# ESP32-H4 register map
Vendor: ESPRESSIF SYSTEMS (SHANGHAI) CO., LTD.; Series: ESP32 H-Series; File version: 1
CPU: RV32IMAC r0p0, little endian, no MPU, no FPU, 0 interrupt priority bits
Address unit: 32 bits
Registers are 32-bit, read-write, reset 0x0 unless marked. A register's access mark holds for its fields unless they carry their own. Offsets are from the block's base; [hi:lo] are bit positions; {n}, {i} and the like mark numbered series.

## UHCI0 — Universal Host Controller Interface 0
Base 0x60014000
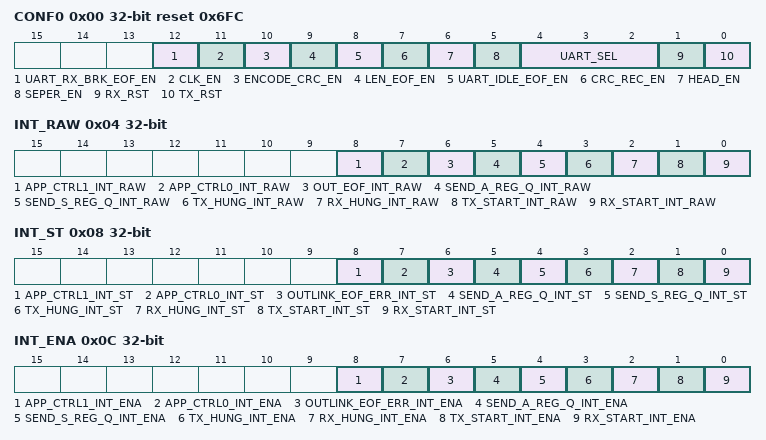
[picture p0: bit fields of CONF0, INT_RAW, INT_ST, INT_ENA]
0x00 CONF0 reset 0x6FC — UHCI configuration register
  [12] UART_RX_BRK_EOF_EN — Configures whether or not to stop UHCI from receiving data after UART has received a NULL frame.\\ 0: Not stop\\ 1: Stop\\
  [11] CLK_EN — Configures clock gating.\\ 0: Support clock only when the application writes registers.\\ 1: Always force the clock on for registers.\\
  [10] ENCODE_CRC_EN — Configures whether or not to enable data integrity check by appending a 16 bit CCITT-CRC to the end of the data.\\ 0: Disable\\ 1: Enable\\
  [9] LEN_EOF_EN — Configures when the UHCI decoder stops receiving data.\\ 0: Stops after receiving 0xC0\\ 1: Stops when the number of received data bytes reach the specified value. When UHCI_HEAD_EN is 1, the specified value is the data length indicated by the UHCI packet header. when UHCI_HEAD_EN is 0, the specified value is the configured value.\\
  [8] UART_IDLE_EOF_EN — Configures whether or not to stop receiving data when UART is idle.\\ 0: Not stop\\ 1: Stop\\
  [7] CRC_REC_EN — Configures whether or not to enable the reception of the 16-bit CRC.\\ 0: Disable\\ 1: Enable\\
  [6] HEAD_EN — Configures whether or not to encode the data packet with a formatting header.\\ 0: Not use formatting header\\ 1: Use formatting header\\
  [5] SEPER_EN — Configures whether or not to separate the data frame with a special character.\\ 0: Not separate\\ 1: Separate\\
  [4:2] UART_SEL — Configures to select which uart to connect with UHCI.\\ 0: UART0\\ 1: UART1\\
  [1] RX_RST — Write 1 and then write 0 to reset the encoder state machine.
  [0] TX_RST — Write 1 and then write 0 to reset the decoder state machine.
0x04 INT_RAW — Raw interrupt status
  [8] APP_CTRL1_INT_RAW — The raw interrupt status of UHCI_APP_CTRL1_INT.
  [7] APP_CTRL0_INT_RAW — The raw interrupt status of UHCI_APP_CTRL0_INT.
  [6] OUT_EOF_INT_RAW — The raw interrupt status of UHCI_OUT_EOF_INT.
  [5] SEND_A_REG_Q_INT_RAW — The raw interrupt status of UHCI_SEND_A_REG_Q_INT.
  [4] SEND_S_REG_Q_INT_RAW — The raw interrupt status of UHCI_SEND_S_REG_Q_INT.
  [3] TX_HUNG_INT_RAW — The raw interrupt status of UHCI_TX_HUNG_INT.
  [2] RX_HUNG_INT_RAW — The raw interrupt status of UHCI_RX_HUNG_INT.
  [1] TX_START_INT_RAW — The raw interrupt status of UHCI_TX_START_INT.
  [0] RX_START_INT_RAW — The raw interrupt status of UHCI_RX_START_INT.
0x08 INT_ST ro — Masked interrupt status
  [8] APP_CTRL1_INT_ST — The masked interrupt status of UHCI_APP_CTRL1_INT.
  [7] APP_CTRL0_INT_ST — The masked interrupt status of UHCI_APP_CTRL0_INT.
  [6] OUTLINK_EOF_ERR_INT_ST — The masked interrupt status of UHCI_OUTLINK_EOF_ERR_INT.
  [5] SEND_A_REG_Q_INT_ST — The masked interrupt status of UHCI_SEND_A_REG_Q_INT.
  [4] SEND_S_REG_Q_INT_ST — The masked interrupt status of UHCI_SEND_S_REG_Q_INT.
  [3] TX_HUNG_INT_ST — The masked interrupt status of UHCI_TX_HUNG_INT.
  [2] RX_HUNG_INT_ST — The masked interrupt status of UHCI_RX_HUNG_INT.
  [1] TX_START_INT_ST — The masked interrupt status of UHCI_TX_START_INT.
  [0] RX_START_INT_ST — The masked interrupt status of UHCI_RX_START_INT.
0x0C INT_ENA — Interrupt enable bits
  [8] APP_CTRL1_INT_ENA — Write 1 to enable UHCI_APP_CTRL1_INT.
  [7] APP_CTRL0_INT_ENA — Write 1 to enable UHCI_APP_CTRL0_INT.
  [6] OUTLINK_EOF_ERR_INT_ENA — Write 1 to enable UHCI_OUTLINK_EOF_ERR_INT.
  [5] SEND_A_REG_Q_INT_ENA — Write 1 to enable UHCI_SEND_A_REG_Q_INT.
  [4] SEND_S_REG_Q_INT_ENA — Write 1 to enable UHCI_SEND_S_REG_Q_INT.
  [3] TX_HUNG_INT_ENA — Write 1 to enable UHCI_TX_HUNG_INT.
  [2] RX_HUNG_INT_ENA — Write 1 to enable UHCI_RX_HUNG_INT.
  [1] TX_START_INT_ENA — Write 1 to enable UHCI_TX_START_INT.
  [0] RX_START_INT_ENA — Write 1 to enable UHCI_RX_START_INT.
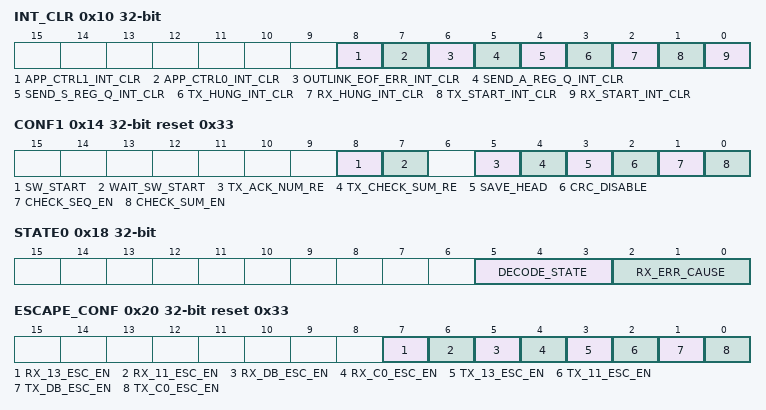
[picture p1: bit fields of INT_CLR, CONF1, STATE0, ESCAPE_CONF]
0x10 INT_CLR wo — Interrupt clear bits
  [8] APP_CTRL1_INT_CLR — Write 1 to clear UHCI_APP_CTRL1_INT.
  [7] APP_CTRL0_INT_CLR — Write 1 to clear UHCI_APP_CTRL0_INT.
  [6] OUTLINK_EOF_ERR_INT_CLR — Write 1 to clear UHCI_OUTLINK_EOF_ERR_INT.
  [5] SEND_A_REG_Q_INT_CLR — Write 1 to clear UHCI_SEND_A_REG_Q_INT.
  [4] SEND_S_REG_Q_INT_CLR — Write 1 to clear UHCI_SEND_S_REG_Q_INT.
  [3] TX_HUNG_INT_CLR — Write 1 to clear UHCI_TX_HUNG_INT.
  [2] RX_HUNG_INT_CLR — Write 1 to clear UHCI_RX_HUNG_INT.
  [1] TX_START_INT_CLR — Write 1 to clear UHCI_TX_START_INT.
  [0] RX_START_INT_CLR — Write 1 to clear UHCI_RX_START_INT.
0x14 CONF1 access per field reset 0x33 — UHCI configuration register
  [8] SW_START wo — Write 1 to send data packets when the encoder state machine is in ST_SW_WAIT state.
  [7] WAIT_SW_START rw — Configures whether or not to put the UHCI encoder state machine to ST_SW_WAIT state.\\ 0: No\\ 1: Yes\\
  [5] TX_ACK_NUM_RE rw — Configures whether or not to encode the data packet with an acknowledgment when a reliable packet is to be transmitted.\\ 0: Not use acknowledgement\\ 1: Use acknowledgement\\
  [4] TX_CHECK_SUM_RE rw — Configures whether or not to encode the data packet with a checksum.\\ 0: Not use checksum\\ 1: Use checksum\\
  [3] SAVE_HEAD rw — Configures whether or not to save the packet header when UHCI receives a data packet.\\ 0: Not save\\ 1: Save\\
  [2] CRC_DISABLE rw — Configures whether or not to enable CRC calculation.\\ 0: Disable\\ 1: Enable\\ Valid only when the Data Integrity Check Present bit in UHCI packet is 1.\\
  [1] CHECK_SEQ_EN rw — Configures whether or not to enable the sequence number check when UHCI receives a data packet.\\ 0: Disable\\ 1: Enable\\
  [0] CHECK_SUM_EN rw — Configures whether or not to enable header checksum validation when UHCI receives a data packet.\\ 0: Disable\\ 1: Enable\\
0x18 STATE0 ro — UHCI receive status
  [5:3] DECODE_STATE — Represents the UHCI decoder status.
  [2:0] RX_ERR_CAUSE — Represents the error type when DMA has received a packet with error.\\ 0: Invalid. No effect\\ 1: Checksum error in the HCI packet\\ 2: Sequence number error in the HCI packet\\ 3: CRC bit error in the HCI packet\\ 4: 0xC0 is found but the received HCI packet is not complete\ 5: 0xC0 is not found when the HCI packet has been received\\ 6: CRC check error\\ 7: Invalid. No effect\\
0x1C STATE1 ro — UHCI transmit status
  [2:0] ENCODE_STATE — Represents the UHCI encoder status.
0x20 ESCAPE_CONF reset 0x33 — Escape character configuration
  [7] RX_13_ESC_EN — Configures whether or not to replace flow control character 0x13 by special characters when DMA sends data.\\ 0: Not replace\\ 1: Replace\\
  [6] RX_11_ESC_EN — Configures whether or not to replace flow control character 0x11 by special characters when DMA sends data.\\ 0: Not replace\\ 1: Replace\\
  [5] RX_DB_ESC_EN — Configures whether or not to replace 0xDB by special characters when DMA sends data.\\ 0: Not replace\\ 1: Replace\\
  [4] RX_C0_ESC_EN — Configures whether or not to replace 0xC0 by special characters when DMA sends data.\\ 0: Not replace\\ 1: Replace\\
  [3] TX_13_ESC_EN — Configures whether or not to decode flow control character 0x13 when DMA receives data.\\ 0: Not decode\\ 1: Decode\\
  [2] TX_11_ESC_EN — Configures whether or not to decode flow control character 0x11 when DMA receives data.\\ 0: Not decode\\ 1: Decode\\
  [1] TX_DB_ESC_EN — Configures whether or not to decode character 0xDB when DMA receives data.\\ 0: Not decode\\ 1: Decode\\
  [0] TX_C0_ESC_EN — Configures whether or not to decode character 0xC0 when DMA receives data.\\ 0: Not decode\\ 1: Decode\\
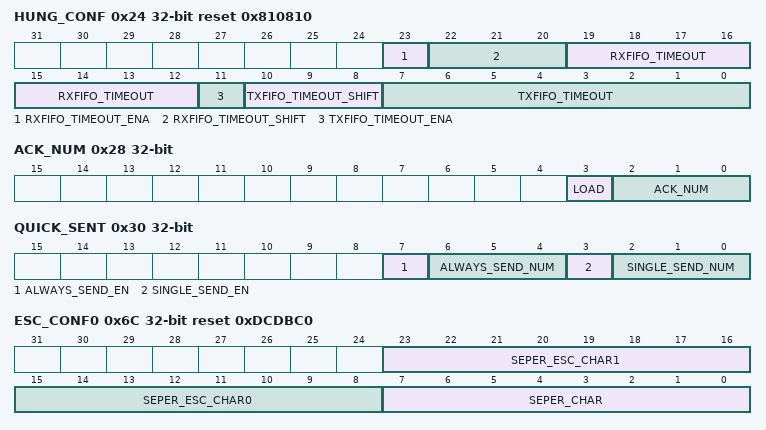
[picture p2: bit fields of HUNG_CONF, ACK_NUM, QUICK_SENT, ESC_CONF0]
0x24 HUNG_CONF reset 0x810810 — Timeout configuration
  [23] RXFIFO_TIMEOUT_ENA — Configures whether or not to enable the DMA data transmission timeout.\\ 0: Disable\\ 1: Enable\\
  [22:20] RXFIFO_TIMEOUT_SHIFT — Configures the upper limit of the timeout counter for RX FIFO.
  [19:12] RXFIFO_TIMEOUT — Configures the timeout value for DMA to read data from RAM.\\Measurement unit: ms.
  [11] TXFIFO_TIMEOUT_ENA — Configures whether or not to enable the data reception timeout for TX FIFO.\\ 0: Disable\\ 1: Enable\\
  [10:8] TXFIFO_TIMEOUT_SHIFT — Configures the upper limit of the timeout counter for TX FIFO.
  [7:0] TXFIFO_TIMEOUT — Configures the timeout value for DMA data reception.\\Measurement unit: ms.
0x28 ACK_NUM access per field — UHCI ACK number configuration
  [3] LOAD wo — Configures whether or not load acknowledgements.\\ 0: Not load\\ 1: Load\\
  [2:0] ACK_NUM rw — Configures the number of acknowledgements used in software flow control.
0x2C RX_HEAD ro — UHCI packet header register
  [31:0] RX_HEAD — Represents the header of the current received packet.
0x30 QUICK_SENT access per field — UHCI quick send configuration register
  [7] ALWAYS_SEND_EN rw — Configures whether or not to enable always_send mode.\\ 0: Disable\\ 1: Enable\\
  [6:4] ALWAYS_SEND_NUM rw — Configures the source of data to be transmitted in always_send mode.\\ 0: Q0 register\\ 1: Q1 register\\ 2: Q2 register\\ 3: Q3 register\\ 4: Q4 register\\ 5: Q5 register\\ 6: Q6 register\\ 7: Invalid. No effect\\
  [3] SINGLE_SEND_EN wo — Write 1 to enable single_send mode.
  [2:0] SINGLE_SEND_NUM rw — Configures the source of data to be transmitted in single_send mode.\\ 0: Q0 register\\ 1: Q1 register\\ 2: Q2 register\\ 3: Q3 register\\ 4: Q4 register\\ 5: Q5 register\\ 6: Q6 register\\ 7: Invalid. No effect\\
{0x34+8i} REG_Q{i}_WORD0 (i=0..6) — Q{i} WORD0 quick send register
  [31:0] SEND_Q{i}_WORD0 — Data to be transmitted in Q{i} register.
{0x38+8i} REG_Q{i}_WORD1 (i=0..5) — Q{i} WORD1 quick send register
  [31:0] SEND_Q{i}_WORD1 — Data to be transmitted in Q{i} register.
0x68 REG_Q6_WORD1 — Q6 WORD1 quick register
  [31:0] SEND_Q6_WORD1 — Data to be transmitted in Q6 register.
0x6C ESC_CONF0 reset 0xDCDBC0 — Escape sequence configuration register 0
  [23:16] SEPER_ESC_CHAR1 — Configures the second character of SLIP escape sequence. The default value is 0xDC.
  [15:8] SEPER_ESC_CHAR0 — Configures the first character of SLIP escape sequence. The default value is 0xDB.
  [7:0] SEPER_CHAR — Configures separators to encode data packets. The default value is 0xC0.
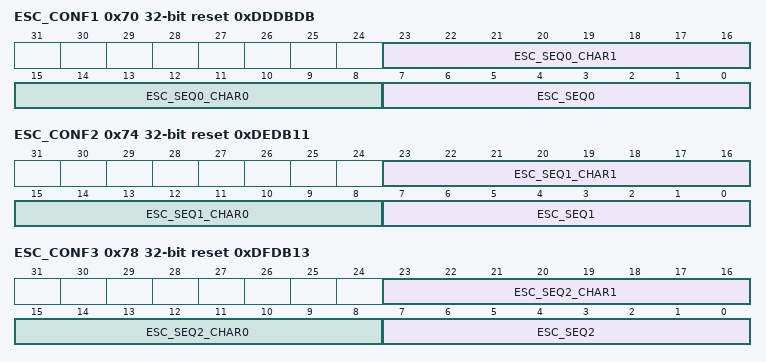
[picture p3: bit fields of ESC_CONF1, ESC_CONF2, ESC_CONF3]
0x70 ESC_CONF1 reset 0xDDDBDB — Escape sequence configuration register 1
  [23:16] ESC_SEQ0_CHAR1 — Configures the second character of SLIP escape sequence. The default value is 0xDD.
  [15:8] ESC_SEQ0_CHAR0 — Configures the first character of SLIP escape sequence. The default value is 0xDB.
  [7:0] ESC_SEQ0 — Configures the character that needs to be encoded. The default value is 0xDB used as the first character of SLIP escape sequence.
0x74 ESC_CONF2 reset 0xDEDB11 — Escape sequence configuration register 2
  [23:16] ESC_SEQ1_CHAR1 — Configures the second character of SLIP escape sequence. The default value is 0xDE.
  [15:8] ESC_SEQ1_CHAR0 — Configures the first character of SLIP escape sequence. The default value is 0xDB.
  [7:0] ESC_SEQ1 — Configures a character that need to be encoded. The default value is 0x11 used as a flow control character.
0x78 ESC_CONF3 reset 0xDFDB13 — Escape sequence configuration register 3
  [23:16] ESC_SEQ2_CHAR1 — Configures the second character of SLIP escape sequence. The default value is 0xDF.
  [15:8] ESC_SEQ2_CHAR0 — Configures the first character of SLIP escape sequence. The default value is 0xDB.
  [7:0] ESC_SEQ2 — Configures the character that needs to be decoded. The default value is 0x13 used as a flow control character.
0x7C PKT_THRES reset 0x80 — Configuration register for packet length
  [12:0] PKT_THRS — Configures the maximum value of the packet length.\\Measurement unit: byte.\\Valid only when UHCI_HEAD_EN is 0.
0x80 DATE reset 0x2201100 — UHCI version control register
  [31:0] DATE — Version control register.
